# STM32H7A3 register map
File version: 3.4
CPU: CM7 r0p1, little endian, MPU, FPU, 4 interrupt priority bits
Registers are 32-bit, read-write, reset 0x0 unless marked. A register's access mark holds for its fields unless they carry their own. Offsets are from the block's base; [hi:lo] are bit positions.

## CAN_CCU — CCU registers
Base 0x4000A800
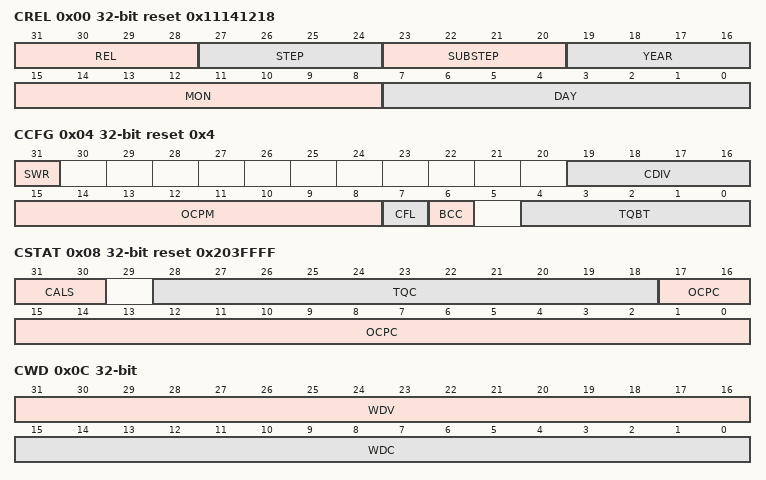
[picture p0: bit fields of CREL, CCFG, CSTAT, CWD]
0x00 CREL reset 0x11141218 — Clock Calibration Unit Core Release Register
  [31:28] REL — Core Release
  [27:24] STEP — Step of Core Release
  [23:20] SUBSTEP — Sub-step of Core Release
  [19:16] YEAR — Time Stamp Year
  [15:8] MON — Time Stamp Month
  [7:0] DAY — Time Stamp Day
0x04 CCFG reset 0x4 — Calibration Configuration Register
  [31] SWR — Software Reset
  [19:16] CDIV — Clock Divider
  [15:8] OCPM — Oscillator Clock Periods Minimum
  [7] CFL — Calibration Field Length
  [6] BCC — Bypass Clock Calibration
  [4:0] TQBT — Time Quanta per Bit Time
0x08 CSTAT reset 0x203FFFF — Calibration Status Register
  [31:30] CALS — Calibration State
  [28:18] TQC — Time Quanta Counter
  [17:0] OCPC — Oscillator Clock Period Counter
0x0C CWD — Calibration Watchdog Register
  [31:16] WDV, [15:0] WDC
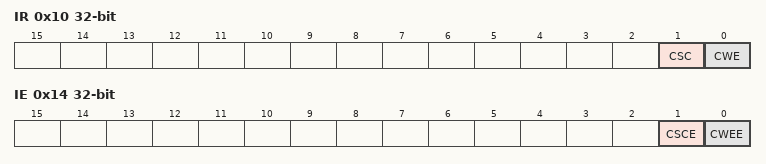
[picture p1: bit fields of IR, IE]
0x10 IR — Clock Calibration Unit Interrupt Register
  [1] CSC — Calibration State Changed
  [0] CWE — Calibration Watchdog Event
0x14 IE — Clock Calibration Unit Interrupt Enable Register
  [1] CSCE — Calibration State Changed Enable
  [0] CWEE — Calibration Watchdog Event Enable

## COMP1
Base 0x58003800
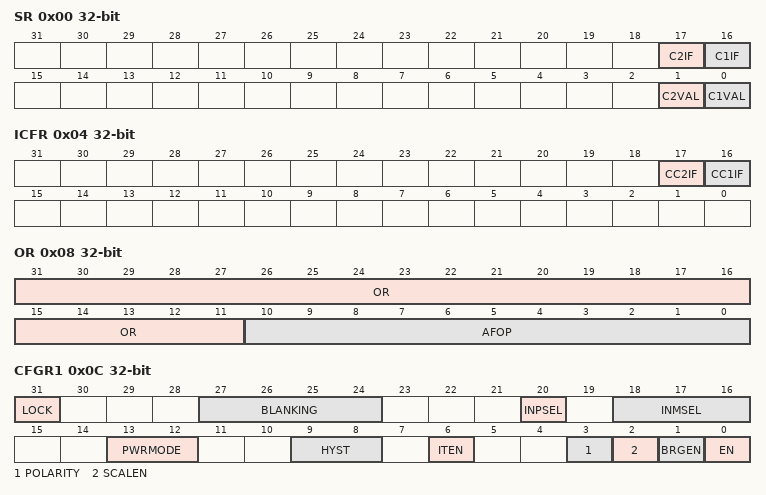
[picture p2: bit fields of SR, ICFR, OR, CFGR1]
0x00 SR ro — Comparator status register
  [17] C2IF — COMP channel 2 Interrupt Flag
  [16] C1IF — COMP channel 1 Interrupt Flag
  [1] C2VAL — COMP channel 2 output status bit
  [0] C1VAL — COMP channel 1 output status bit
0x04 ICFR wo — Comparator interrupt clear flag register
  [17] CC2IF — Clear COMP channel 2 Interrupt Flag
  [16] CC1IF — Clear COMP channel 1 Interrupt Flag
0x08 OR — Comparator option register
  [31:11] OR — Option Register
  [10:0] AFOP — Selection of source for alternate function of output ports
0x0C CFGR1 — Comparator configuration register 1
  [31] LOCK — Lock bit
  [27:24] BLANKING — COMP channel 1 blanking source selection bits
  [20] INPSEL — COMP channel 1 non-inverting input selection bit
  [18:16] INMSEL — COMP channel 1 inverting input selection field
  [13:12] PWRMODE — Power Mode of the COMP channel 1
  [9:8] HYST — COMP channel 1 hysteresis selection bits
  [6] ITEN — COMP channel 1 interrupt enable
  [3] POLARITY — COMP channel 1 polarity selection bit
  [2] SCALEN — Voltage scaler enable bit
  [1] BRGEN — Scaler bridge enable
  [0] EN — COMP channel 1 enable bit
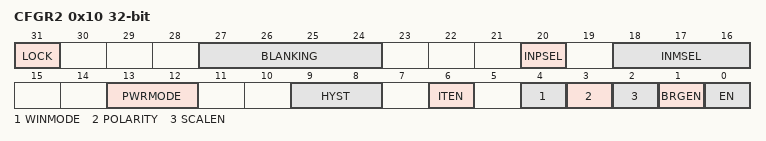
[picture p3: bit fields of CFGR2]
0x10 CFGR2 — Comparator configuration register 2
  [31] LOCK — Lock bit
  [27:24] BLANKING — COMP channel 1 blanking source selection bits
  [20] INPSEL — COMP channel 1 non-inverting input selection bit
  [18:16] INMSEL — COMP channel 1 inverting input selection field
  [13:12] PWRMODE — Power Mode of the COMP channel 1
  [9:8] HYST — COMP channel 1 hysteresis selection bits
  [6] ITEN — COMP channel 1 interrupt enable
  [4] WINMODE — Window comparator mode selection bit
  [3] POLARITY — COMP channel 1 polarity selection bit
  [2] SCALEN — Voltage scaler enable bit
  [1] BRGEN — Scaler bridge enable
  [0] EN — COMP channel 1 enable bit

## CRC — Cryptographic processor
Base 0x40023000
0x00 DR reset 0xFFFFFFFF — Data register
  [31:0] DR — Data Register
0x00 DR8 8-bit reset 0xFF (alternate view of DR) — Data register - byte sized
  [7:0] DR8 — Data register bits
0x00 DR16 16-bit reset 0xFFFF (alternate view of DR) — Data register - half-word sized
  [15:0] DR16 — Data register bits
0x04 IDR — Independent Data register
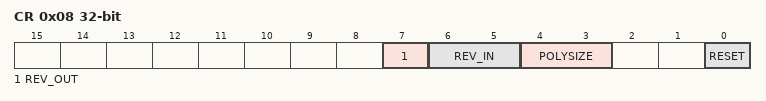
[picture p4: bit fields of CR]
0x08 CR access per field — Control register
  [7] REV_OUT rw — Reverse output data
    0=Normal (Bit order not affected); 1=Reversed (Bit reversed output)
  [6:5] REV_IN rw — Reverse input data
    0=Normal (Bit order not affected); 1=Byte (Bit reversal done by byte); 2=HalfWord (Bit reversal done by half-word); 3=Word (Bit reversal done by word)
  [4:3] POLYSIZE rw — Polynomial size
    0=32-bit polynomial; 1=16-bit polynomial; 2=8-bit polynomial; 3=7-bit polynomial
  [0] RESET wo — RESET bit
    1=Resets the CRC calculation unit and sets the data register to 0xFFFF FFFF
0x10 INIT — Initial CRC value
  [31:0] INIT — Programmable initial CRC value
0x14 POL — CRC polynomial
  [31:0] POL — Programmable polynomial
